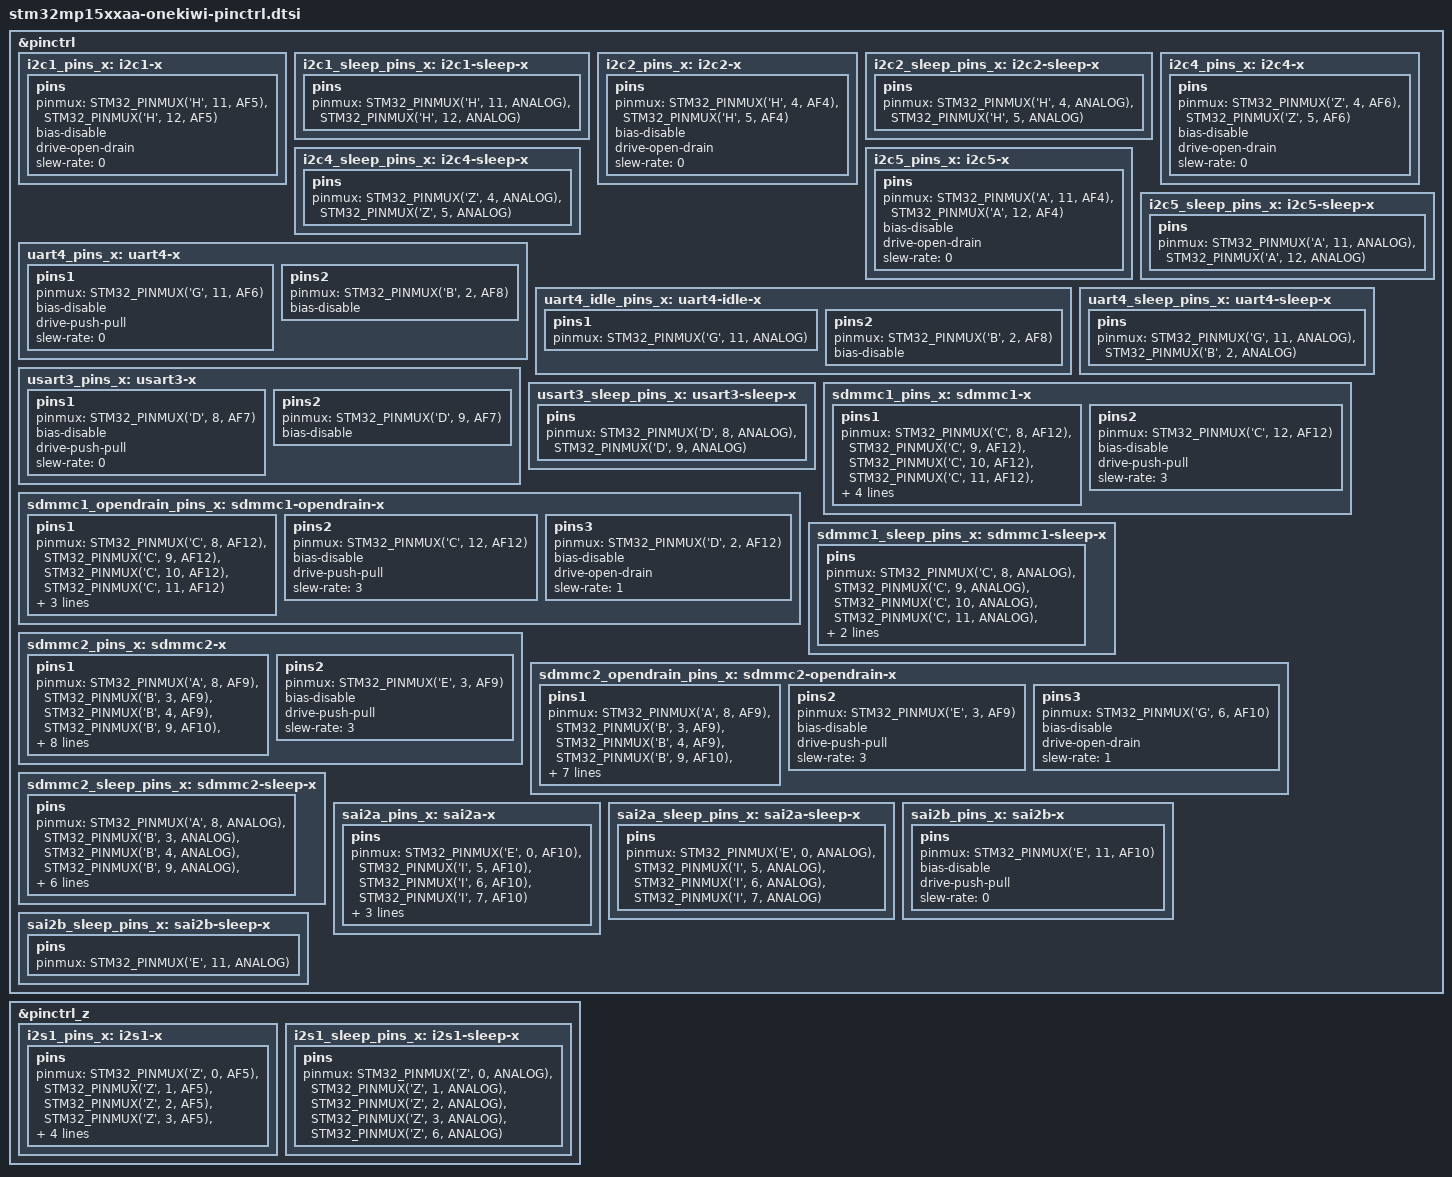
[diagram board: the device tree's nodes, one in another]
// SPDX-License-Identifier: (GPL-2.0+ OR BSD-3-Clause)
/*
 * Copyright (C) STMicroelectronics 2017 - All Rights Reserved
 * Author: Ludovic Barre <ludovic.barre@st.com> for STMicroelectronics.
 */
#include <dt-bindings/pinctrl/stm32-pinfunc.h>

&pinctrl {
	i2c1_pins_x: i2c1-x {
		pins {
			pinmux = <STM32_PINMUX('H', 11, AF5)>, /* I2C1_SCL */
					 <STM32_PINMUX('H', 12, AF5)>; /* I2C1_SDA */
			bias-disable;
			drive-open-drain;
			slew-rate = <0>;
		};
	};

	i2c1_sleep_pins_x: i2c1-sleep-x {
		pins {
			pinmux = <STM32_PINMUX('H', 11, ANALOG)>, /* I2C1_SCL */
					 <STM32_PINMUX('H', 12, ANALOG)>; /* I2C1_SDA */
		};
	};

	i2c2_pins_x: i2c2-x {
		pins {
			pinmux = <STM32_PINMUX('H', 4, AF4)>, /* I2C2_SCL */
					 <STM32_PINMUX('H', 5, AF4)>; /* I2C2_SDA */
			bias-disable;
			drive-open-drain;
			slew-rate = <0>;
		};
	};

	i2c2_sleep_pins_x: i2c2-sleep-x {
		pins {
			pinmux = <STM32_PINMUX('H', 4, ANALOG)>, /* I2C2_SCL */
					 <STM32_PINMUX('H', 5, ANALOG)>; /* I2C2_SDA */
		};
	};

	i2c4_pins_x: i2c4-x {
		pins {
			pinmux = <STM32_PINMUX('Z', 4, AF6)>, /* I2C4_SCL */
				 <STM32_PINMUX('Z', 5, AF6)>; /* I2C4_SDA */
			bias-disable;
			drive-open-drain;
			slew-rate = <0>;
		};
	};

	i2c4_sleep_pins_x: i2c4-sleep-x {
		pins {
			pinmux = <STM32_PINMUX('Z', 4, ANALOG)>, /* I2C4_SCL */
				 <STM32_PINMUX('Z', 5, ANALOG)>; /* I2C4_SDA */
		};
	};

	i2c5_pins_x: i2c5-x {
		pins {
			pinmux = <STM32_PINMUX('A', 11, AF4)>, /* I2C5_SCL */
					 <STM32_PINMUX('A', 12, AF4)>; /* I2C5_SDA */
			bias-disable;
			drive-open-drain;
			slew-rate = <0>;
		};
	};

	i2c5_sleep_pins_x: i2c5-sleep-x {
		pins {
			pinmux = <STM32_PINMUX('A', 11, ANALOG)>, /* I2C5_SCL */
					 <STM32_PINMUX('A', 12, ANALOG)>; /* I2C5_SDA */
		};
	};

	uart4_pins_x: uart4-x {
		pins1 {
			pinmux = <STM32_PINMUX('G', 11, AF6)>; /* UART4_TX */
			bias-disable;
			drive-push-pull;
			slew-rate = <0>;
		};
		pins2 {
			pinmux = <STM32_PINMUX('B', 2, AF8)>; /* UART4_RX */
			bias-disable;
		};
	};

	uart4_idle_pins_x: uart4-idle-x {
		pins1 {
			pinmux = <STM32_PINMUX('G', 11, ANALOG)>; /* UART4_TX */
		};
		pins2 {
			pinmux = <STM32_PINMUX('B', 2, AF8)>; /* UART4_RX */
			bias-disable;
		};
	};

	uart4_sleep_pins_x: uart4-sleep-x {
		pins {
			pinmux = <STM32_PINMUX('G', 11, ANALOG)>, /* UART4_TX */
				 <STM32_PINMUX('B', 2, ANALOG)>; /* UART4_RX */
		};
	};

	usart3_pins_x: usart3-x {
		pins1 {
			pinmux = <STM32_PINMUX('D', 8, AF7)>; /* USART3_TX */
			bias-disable;
			drive-push-pull;
			slew-rate = <0>;
		};
		pins2 {
			pinmux = <STM32_PINMUX('D', 9, AF7)>; /* USART3_RX */
			bias-disable;
		};
	};

	usart3_sleep_pins_x: usart3-sleep-x {
		pins {
			pinmux = <STM32_PINMUX('D', 8, ANALOG)>, /* USART3_TX */
					 <STM32_PINMUX('D', 9, ANALOG)>; /* USART3_RX */
		};
	};

	sdmmc1_pins_x: sdmmc1-x {
		pins1 {
			pinmux = <STM32_PINMUX('C', 8, AF12)>, /* SDMMC1_D0 */
					 <STM32_PINMUX('C', 9, AF12)>, /* SDMMC1_D1 */
					 <STM32_PINMUX('C', 10, AF12)>, /* SDMMC1_D2 */
					 <STM32_PINMUX('C', 11, AF12)>, /* SDMMC1_D3 */
					 <STM32_PINMUX('D', 2, AF12)>; /* SDMMC1_CMD */
			bias-disable;
			drive-push-pull;
			slew-rate = <1>;
		};
		pins2 {
			pinmux = <STM32_PINMUX('C', 12, AF12)>; /* SDMMC1_CK */
			bias-disable;
			drive-push-pull;
			slew-rate = <3>;
		};
	};

	sdmmc1_opendrain_pins_x: sdmmc1-opendrain-x {
		pins1 {
			pinmux = <STM32_PINMUX('C', 8, AF12)>, /* SDMMC1_D0 */
					 <STM32_PINMUX('C', 9, AF12)>, /* SDMMC1_D1 */
					 <STM32_PINMUX('C', 10, AF12)>, /* SDMMC1_D2 */
					 <STM32_PINMUX('C', 11, AF12)>; /* SDMMC1_D3 */
			bias-disable;
			drive-push-pull;
			slew-rate = <1>;
		};
		pins2 {
			pinmux = <STM32_PINMUX('C', 12, AF12)>; /* SDMMC1_CK */
			bias-disable;
			drive-push-pull;
			slew-rate = <3>;
		};
		pins3 {
			pinmux = <STM32_PINMUX('D', 2, AF12)>; /* SDMMC1_CMD */
			bias-disable;
			drive-open-drain;
			slew-rate = <1>;
		};
	};

	sdmmc1_sleep_pins_x: sdmmc1-sleep-x {
		pins {
			pinmux = <STM32_PINMUX('C', 8, ANALOG)>, /* SDMMC1_D0 */
					 <STM32_PINMUX('C', 9, ANALOG)>, /* SDMMC1_D1 */
					 <STM32_PINMUX('C', 10, ANALOG)>, /* SDMMC1_D2 */
					 <STM32_PINMUX('C', 11, ANALOG)>, /* SDMMC1_D3 */
					 <STM32_PINMUX('C', 12, ANALOG)>, /* SDMMC1_CK */
					 <STM32_PINMUX('D', 2, ANALOG)>; /* SDMMC1_CMD */
		};
	};

	sdmmc2_pins_x: sdmmc2-x {
		pins1 {
			pinmux = <STM32_PINMUX('A', 8, AF9)>, /* SDMMC2_D4 */
					 <STM32_PINMUX('B', 3, AF9)>, /* SDMMC2_D2 */
					 <STM32_PINMUX('B', 4, AF9)>, /* SDMMC2_D3 */
					 <STM32_PINMUX('B', 9, AF10)>, /* SDMMC2_D5 */
					 <STM32_PINMUX('B', 14, AF9)>, /* SDMMC2_D0 */
					 <STM32_PINMUX('B', 15, AF9)>, /* SDMMC2_D1 */
					 <STM32_PINMUX('D', 3, AF9)>, /* SDMMC2_D7 */
					 <STM32_PINMUX('E', 5, AF9)>, /* SDMMC2_D6 */
					 <STM32_PINMUX('G', 6, AF10)>; /* SDMMC2_CMD */
			bias-disable;
			drive-push-pull;
			slew-rate = <1>;
		};
		pins2 {
			pinmux = <STM32_PINMUX('E', 3, AF9)>; /* SDMMC2_CK */
			bias-disable;
			drive-push-pull;
			slew-rate = <3>;
		};
	};

	sdmmc2_opendrain_pins_x: sdmmc2-opendrain-x {
		pins1 {
			pinmux = <STM32_PINMUX('A', 8, AF9)>, /* SDMMC2_D4 */
					 <STM32_PINMUX('B', 3, AF9)>, /* SDMMC2_D2 */
					 <STM32_PINMUX('B', 4, AF9)>, /* SDMMC2_D3 */
					 <STM32_PINMUX('B', 9, AF10)>, /* SDMMC2_D5 */
					 <STM32_PINMUX('B', 14, AF9)>, /* SDMMC2_D0 */
					 <STM32_PINMUX('B', 15, AF9)>, /* SDMMC2_D1 */
					 <STM32_PINMUX('D', 3, AF9)>, /* SDMMC2_D7 */
					 <STM32_PINMUX('E', 5, AF9)>; /* SDMMC2_D6 */
			bias-disable;
			drive-push-pull;
			slew-rate = <1>;
		};
		pins2 {
			pinmux = <STM32_PINMUX('E', 3, AF9)>; /* SDMMC2_CK */
			bias-disable;
			drive-push-pull;
			slew-rate = <3>;
		};
		pins3 {
			pinmux = <STM32_PINMUX('G', 6, AF10)>; /* SDMMC2_CMD */
			bias-disable;
			drive-open-drain;
			slew-rate = <1>;
		};
	};

	sdmmc2_sleep_pins_x: sdmmc2-sleep-x {
		pins {
			pinmux = <STM32_PINMUX('A', 8, ANALOG)>, /* SDMMC2_D4 */
					 <STM32_PINMUX('B', 3, ANALOG)>, /* SDMMC2_D2 */
					 <STM32_PINMUX('B', 4, ANALOG)>, /* SDMMC2_D3 */
					 <STM32_PINMUX('B', 9, ANALOG)>, /* SDMMC2_D5 */
					 <STM32_PINMUX('B', 14, ANALOG)>, /* SDMMC2_D0 */
					 <STM32_PINMUX('B', 15, ANALOG)>, /* SDMMC2_D1 */
					 <STM32_PINMUX('D', 3, ANALOG)>, /* SDMMC2_D7 */
					 <STM32_PINMUX('E', 3, ANALOG)>, /* SDMMC2_CK */
					 <STM32_PINMUX('E', 5, ANALOG)>, /* SDMMC2_D6 */
					 <STM32_PINMUX('G', 6, ANALOG)>; /* SDMMC2_CMD */
		};
	};

	sai2a_pins_x: sai2a-x {
		pins {
			pinmux = <STM32_PINMUX('E', 0, AF10)>, /* SAI2_MCLK_A */
					 <STM32_PINMUX('I', 5, AF10)>, /* SAI2_SCK_A */
					 <STM32_PINMUX('I', 6, AF10)>, /* SAI2_SD_A */
					 <STM32_PINMUX('I', 7, AF10)>; /* SAI2_FS_A */
			bias-disable;
			drive-push-pull;
			slew-rate = <0>;
		};
	};

	sai2a_sleep_pins_x: sai2a-sleep-x {
		pins {
			pinmux = <STM32_PINMUX('E', 0, ANALOG)>, /* SAI2_MCLK_A */
					 <STM32_PINMUX('I', 5, ANALOG)>, /* SAI2_SCK_A */
					 <STM32_PINMUX('I', 6, ANALOG)>, /* SAI2_SD_A */
					 <STM32_PINMUX('I', 7, ANALOG)>; /* SAI2_FS_A */
		};
	};

	sai2b_pins_x: sai2b-x {
		pins {
			pinmux = <STM32_PINMUX('E', 11, AF10)>; /* SAI2_SD_B */
			bias-disable;
			drive-push-pull;
			slew-rate = <0>;
		};
	};

	sai2b_sleep_pins_x: sai2b-sleep-x {
		pins {
			pinmux = <STM32_PINMUX('E', 11, ANALOG)>; /* SAI2_SD_B */
		};
	};
};

&pinctrl_z {
	i2s1_pins_x: i2s1-x {
		pins {
			pinmux = <STM32_PINMUX('Z', 0, AF5)>, /* I2S1_CK */
					 <STM32_PINMUX('Z', 1, AF5)>, /* I2S1_SDI */
					 <STM32_PINMUX('Z', 2, AF5)>, /* I2S1_SDO */
					 <STM32_PINMUX('Z', 3, AF5)>, /* I2S1_WS */
					 <STM32_PINMUX('Z', 6, AF5)>; /* I2S1_MCK */
			bias-disable;
			drive-push-pull;
			slew-rate = <1>;
		};
	};

	i2s1_sleep_pins_x: i2s1-sleep-x {
		pins {
			pinmux = <STM32_PINMUX('Z', 0, ANALOG)>, /* I2S1_CK */
					 <STM32_PINMUX('Z', 1, ANALOG)>, /* I2S1_SDI */
					 <STM32_PINMUX('Z', 2, ANALOG)>, /* I2S1_SDO */
					 <STM32_PINMUX('Z', 3, ANALOG)>, /* I2S1_WS */
					 <STM32_PINMUX('Z', 6, ANALOG)>; /* I2S1_MCK */
		};
	};
};
